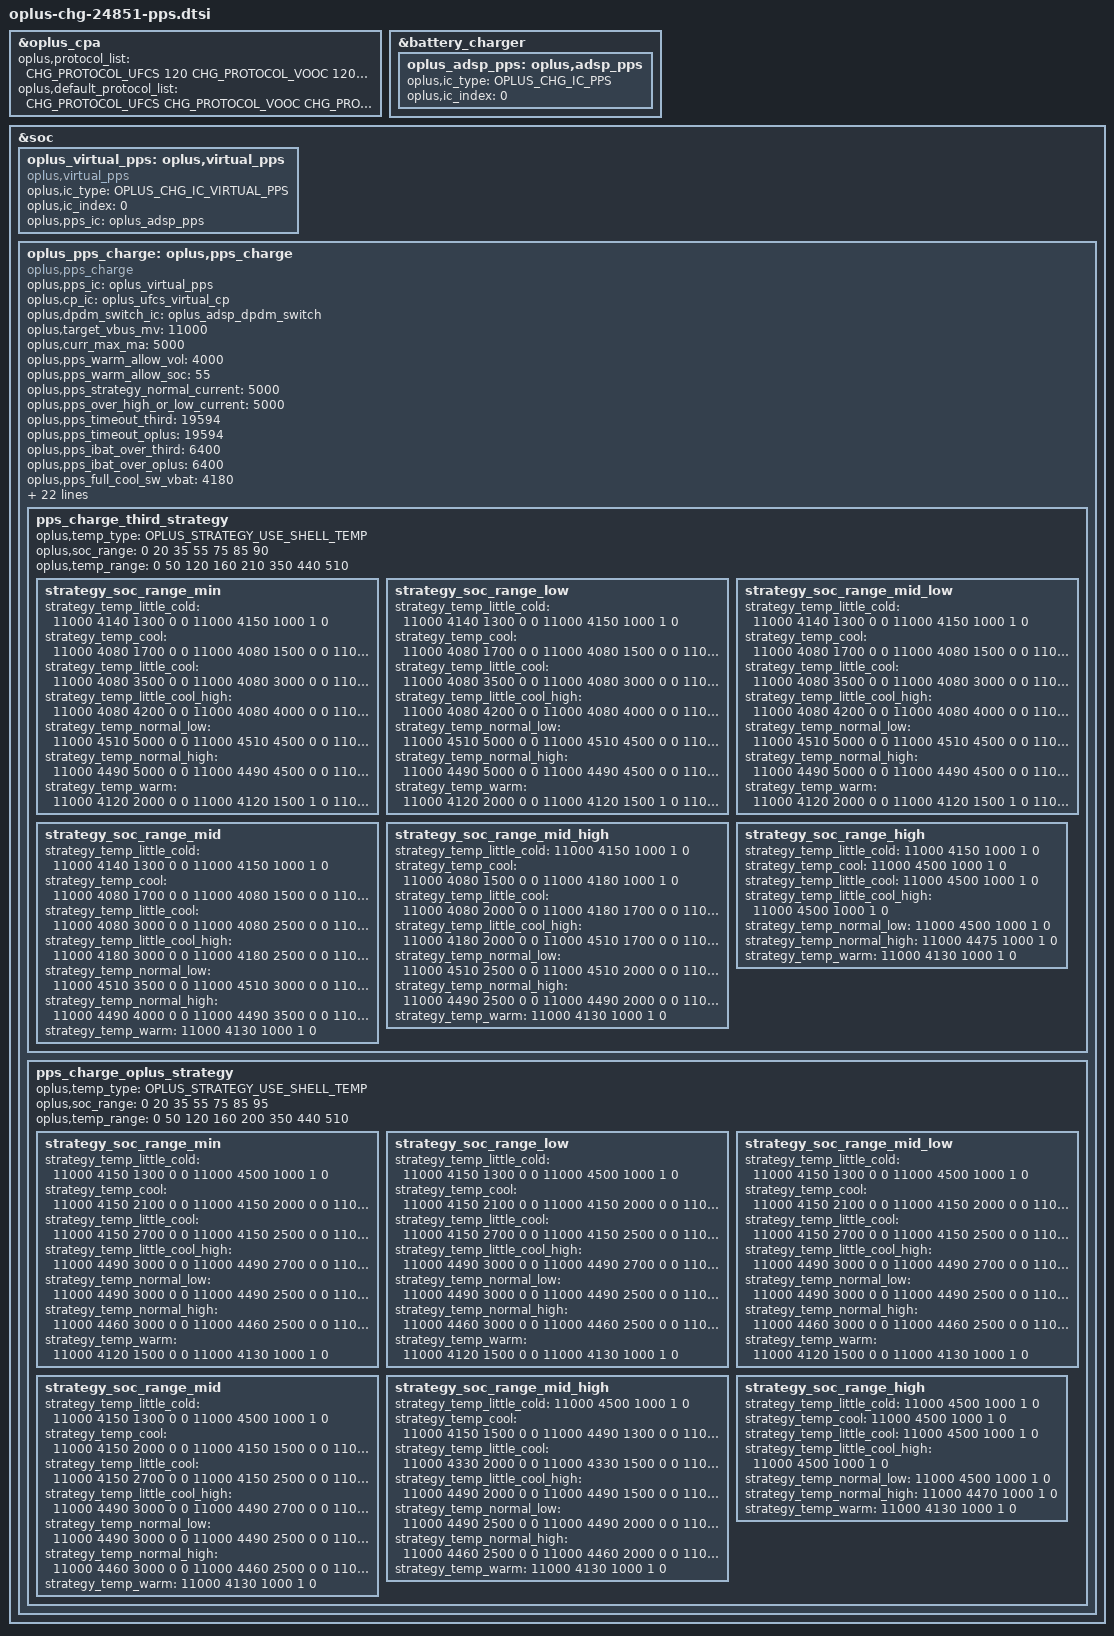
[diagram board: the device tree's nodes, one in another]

&oplus_cpa {
	oplus,protocol_list = <CHG_PROTOCOL_UFCS  120
				   CHG_PROTOCOL_VOOC 120
				   CHG_PROTOCOL_PPS  55
				   CHG_PROTOCOL_PD   18
				   CHG_PROTOCOL_QC   18>;
	oplus,default_protocol_list = <CHG_PROTOCOL_UFCS
					   CHG_PROTOCOL_VOOC
					   CHG_PROTOCOL_PPS
					   CHG_PROTOCOL_PD>;
};

&battery_charger {
	oplus_adsp_pps: oplus,adsp_pps {
		oplus,ic_type = <OPLUS_CHG_IC_PPS>;
		oplus,ic_index = <0>;
	};
};

&soc {
	oplus_virtual_pps: oplus,virtual_pps {
		compatible = "oplus,virtual_pps";

		oplus,ic_type = <OPLUS_CHG_IC_VIRTUAL_PPS>;
		oplus,ic_index = <0>;
		oplus,pps_ic = <&oplus_adsp_pps>;
	};
	oplus_pps_charge: oplus,pps_charge {
		compatible = "oplus,pps_charge";
		oplus,pps_ic = <&oplus_virtual_pps>;
		oplus,cp_ic = <&oplus_ufcs_virtual_cp>;
		oplus,dpdm_switch_ic = <&oplus_adsp_dpdm_switch>;

		oplus,target_vbus_mv = <11000>;
		oplus,curr_max_ma = <5000>;

		oplus,pps_warm_allow_vol = <4000>;
		oplus,pps_warm_allow_soc = <55>;
		oplus,pps_strategy_normal_current = <5000>;
		oplus,pps_over_high_or_low_current = <5000>;
		oplus,pps_timeout_third = <19594>;
		oplus,pps_timeout_oplus = <19594>;
		oplus,pps_ibat_over_third = <6400>;
		oplus,pps_ibat_over_oplus = <6400>;
		oplus,pps_full_cool_sw_vbat = <4180>;
		oplus,pps_full_normal_sw_vbat = <4520>;
		oplus,pps_full_normal_hw_vbat = <4560>;
		oplus,pps_full_ffc_vbat = <4550>;
		oplus,pps_full_warm_vbat = <4130>;
		oplus,pps_full_cool_sw_vbat_third = <4180>;
		oplus,pps_full_normal_sw_vbat_third= <4520>;
		oplus,pps_full_normal_hw_vbat_third = <4560>;
		oplus,pps_current_change_timeout = <100>;
		oplus,pps_strategy_batt_high_temp = <410 420 430 400 410 420>;
		oplus,pps_strategy_high_current = <5000 5000 2000 5000 5000 5000>;
		oplus,pps_little_cool_high_temp = <210>;
		oplus,pps_low_temp = <50>;
		oplus,curve_strategy_name = "pps_ufcs_curve_v2";
		oplus,pps_charge_strategy_soc = <0 20 35 55 75 85>;
		oplus,pps_charge_strategy_temp = <50 50 120 160 350 440 510>;

		oplus,plc_strategy-data = <&cp_2t1_simple_strategy>;
		oplus,plc_strategy-names = "default";

		pps_charge_third_strategy {
			oplus,temp_type = <OPLUS_STRATEGY_USE_SHELL_TEMP>;
			oplus,soc_range = <0 20 35 55 75 85 90>;
			oplus,temp_range = <0 50 120 160 210 350 440 510>;

			strategy_soc_range_min {
				strategy_temp_little_cold =	<11000 4140 1300 0 0
								11000 4150 1000 1 0>;
				strategy_temp_cool =		<11000 4080 1700 0 0
								11000 4080 1500 0 0
								11000 4180 1000 1 0>;
				strategy_temp_little_cool =	<11000 4080 3500 0 0
								11000 4080 3000 0 0
								11000 4080 2500 0 0
								11000 4080 2000 0 0
								11000 4180 1700 0 0
								11000 4180 1500 0 0
								11000 4520 1000 1 0>;
				strategy_temp_little_cool_high = <11000 4080 4200 0 0
								11000 4080 4000 0 0
								11000 4180 3500 0 0
								11000 4180 3000 0 0
								11000 4180 2500 0 0
								11000 4180 2000 0 0
								11000 4510 1700 0 0
								11000 4510 1500 0 0
								11000 4520 1000 1 0>;
				strategy_temp_normal_low =	<11000 4510 5000 0 0
								11000 4510 4500 0 0
								11000 4510 4000 0 0
								11000 4510 3500 0 0
								11000 4510 3000 0 0
								11000 4510 2500 0 0
								11000 4510 2000 0 0
								11000 4510 1500 0 0
								11000 4520 1000 1 0>;
				strategy_temp_normal_high =	<11000 4490 5000 0 0
								11000 4490 4500 0 0
								11000 4490 4000 0 0
								11000 4490 3500 0 0
								11000 4490 3000 0 0
								11000 4490 2500 0 0
								11000 4490 2000 0 0
								11000 4490 1500 0 0
								11000 4500 1000 1 0>;
				strategy_temp_warm =		<11000 4120 2000 0 0
								11000 4120 1500 1 0
								11000 4130 1000 1 0>;
			};
			strategy_soc_range_low {
				strategy_temp_little_cold =	<11000 4140 1300 0 0
								11000 4150 1000 1 0>;
				strategy_temp_cool =		<11000 4080 1700 0 0
								11000 4080 1500 0 0
								11000 4180 1000 1 0>;
				strategy_temp_little_cool =	<11000 4080 3500 0 0
								11000 4080 3000 0 0
								11000 4080 2500 0 0
								11000 4080 2000 0 0
								11000 4180 1700 0 0
								11000 4180 1500 0 0
								11000 4520 1000 1 0>;
				strategy_temp_little_cool_high = <11000 4080 4200 0 0
								11000 4080 4000 0 0
								11000 4180 3500 0 0
								11000 4180 3000 0 0
								11000 4180 2500 0 0
								11000 4180 2000 0 0
								11000 4510 1700 0 0
								11000 4510 1500 0 0
								11000 4520 1000 1 0>;
				strategy_temp_normal_low =	<11000 4510 5000 0 0
								11000 4510 4500 0 0
								11000 4510 4000 0 0
								11000 4510 3500 0 0
								11000 4510 3000 0 0
								11000 4510 2500 0 0
								11000 4510 2000 0 0
								11000 4510 1500 0 0
								11000 4520 1000 1 0>;
				strategy_temp_normal_high =	<11000 4490 5000 0 0
								11000 4490 4500 0 0
								11000 4490 4000 0 0
								11000 4490 3500 0 0
								11000 4490 3000 0 0
								11000 4490 2500 0 0
								11000 4490 2000 0 0
								11000 4490 1500 0 0
								11000 4500 1000 1 0>;
				strategy_temp_warm =		<11000 4120 2000 0 0
								11000 4120 1500 1 0
								11000 4130 1000 1 0>;
			};
			strategy_soc_range_mid_low {
				strategy_temp_little_cold =	<11000 4140 1300 0 0
								11000 4150 1000 1 0>;
				strategy_temp_cool =		<11000 4080 1700 0 0
								11000 4080 1500 0 0
								11000 4180 1000 1 0>;
				strategy_temp_little_cool =	<11000 4080 3500 0 0
								11000 4080 3000 0 0
								11000 4080 2500 0 0
								11000 4080 2000 0 0
								11000 4180 1700 0 0
								11000 4180 1500 0 0
								11000 4520 1000 1 0>;
				strategy_temp_little_cool_high = <11000 4080 4200 0 0
								11000 4080 4000 0 0
								11000 4180 3500 0 0
								11000 4180 3000 0 0
								11000 4180 2500 0 0
								11000 4180 2000 0 0
								11000 4510 1700 0 0
								11000 4510 1500 0 0
								11000 4520 1000 1 0>;
				strategy_temp_normal_low =	<11000 4510 5000 0 0
								11000 4510 4500 0 0
								11000 4510 4000 0 0
								11000 4510 3500 0 0
								11000 4510 3000 0 0
								11000 4510 2500 0 0
								11000 4510 2000 0 0
								11000 4510 1500 0 0
								11000 4520 1000 1 0>;
				strategy_temp_normal_high =	<11000 4490 5000 0 0
								11000 4490 4500 0 0
								11000 4490 4000 0 0
								11000 4490 3500 0 0
								11000 4490 3000 0 0
								11000 4490 2500 0 0
								11000 4490 2000 0 0
								11000 4490 1500 0 0
								11000 4500 1000 1 0>;
				strategy_temp_warm =		<11000 4120 2000 0 0
								11000 4120 1500 1 0
								11000 4130 1000 1 0>;
			};
			strategy_soc_range_mid {
				strategy_temp_little_cold =	<11000 4140 1300 0 0
								11000 4150 1000 1 0>;
				strategy_temp_cool =		<11000 4080 1700 0 0
								11000 4080 1500 0 0
								11000 4180 1000 1 0>;
				strategy_temp_little_cool =	<11000 4080 3000 0 0
								11000 4080 2500 0 0
								11000 4080 2000 0 0
								11000 4180 1700 0 0
								11000 4180 1500 0 0
								11000 4520 1000 1 0>;
				strategy_temp_little_cool_high = <11000 4180 3000 0 0
								11000 4180 2500 0 0
								11000 4180 2000 0 0
								11000 4510 1700 0 0
								11000 4510 1500 0 0
								11000 4520 1000 1 0>;
				strategy_temp_normal_low =	<11000 4510 3500 0 0
								11000 4510 3000 0 0
								11000 4510 2500 0 0
								11000 4510 2000 0 0
								11000 4510 1500 0 0
								11000 4520 1000 1 0>;
				strategy_temp_normal_high =	<11000 4490 4000 0 0
								11000 4490 3500 0 0
								11000 4490 3000 0 0
								11000 4490 2500 0 0
								11000 4490 2000 0 0
								11000 4490 1500 0 0
								11000 4500 1000 1 0>;
				strategy_temp_warm =		<11000 4130 1000 1 0>;
			};
			strategy_soc_range_mid_high {
				strategy_temp_little_cold =	<11000 4150 1000 1 0>;
				strategy_temp_cool =		<11000 4080 1500 0 0
								11000 4180 1000 1 0>;
				strategy_temp_little_cool =	<11000 4080 2000 0 0
								11000 4180 1700 0 0
								11000 4180 1500 0 0
								11000 4520 1000 1 0>;
				strategy_temp_little_cool_high = <11000 4180 2000 0 0
								11000 4510 1700 0 0
								11000 4510 1500 0 0
								11000 4520 1000 1 0>;
				strategy_temp_normal_low =	<11000 4510 2500 0 0
								11000 4510 2000 0 0
								11000 4510 1500 0 0
								11000 4520 1000 1 0>;
				strategy_temp_normal_high =	<11000 4490 2500 0 0
								11000 4490 2000 0 0
								11000 4490 1500 0 0
								11000 4500 1000 1 0>;
				strategy_temp_warm =		<11000 4130 1000 1 0>;
			};
			strategy_soc_range_high {
				strategy_temp_little_cold =	<11000 4150 1000 1 0>;
				strategy_temp_cool =		<11000 4500 1000 1 0>;
				strategy_temp_little_cool =	<11000 4500 1000 1 0>;
				strategy_temp_little_cool_high = <11000 4500 1000 1 0>;
				strategy_temp_normal_low =	<11000 4500 1000 1 0>;
				strategy_temp_normal_high =	<11000 4475 1000 1 0>;
				strategy_temp_warm =		<11000 4130 1000 1 0>;
			};
		};

		pps_charge_oplus_strategy {
			oplus,temp_type = <OPLUS_STRATEGY_USE_SHELL_TEMP>;
			oplus,soc_range = <0 20 35 55 75 85 95>;
			oplus,temp_range = <0 50 120 160 200 350 440 510>;

			strategy_soc_range_min {
				strategy_temp_little_cold =	<11000 4150 1300 0 0
								11000 4500 1000 1 0>;
				strategy_temp_cool =		<11000 4150 2100 0 0
								11000 4150 2000 0 0
								11000 4150 1500 0 0
								11000 4490 1300 0 0
								11000 4500 1000 1 0>;
				strategy_temp_little_cool =	<11000 4150 2700 0 0
								11000 4150 2500 0 0
								11000 4330 2100 0 0
								11000 4330 2000 0 0
								11000 4330 1500 0 0
								11000 4490 1300 0 0
								11000 4500 1000 1 0>;
				strategy_temp_little_cool_high = <11000 4490 3000 0 0
								11000 4490 2700 0 0
								11000 4490 2500 0 0
								11000 4490 2000 0 0
								11000 4490 1500 0 0
								11000 4500 1000 1 0>;
				strategy_temp_normal_low =	<11000 4490 3000 0 0
								11000 4490 2500 0 0
								11000 4490 2000 0 0
								11000 4490 1500 0 0
								11000 4500 1000 1 0>;
				strategy_temp_normal_high =	<11000 4460 3000 0 0
								11000 4460 2500 0 0
								11000 4460 2000 0 0
								11000 4460 1500 0 0
								11000 4470 1000 1 0>;
				strategy_temp_warm =		<11000 4120 1500 0 0
								11000 4130 1000 1 0>;
			};
			strategy_soc_range_low {
				strategy_temp_little_cold =	<11000 4150 1300 0 0
								11000 4500 1000 1 0>;
				strategy_temp_cool =		<11000 4150 2100 0 0
								11000 4150 2000 0 0
								11000 4150 1500 0 0
								11000 4490 1300 0 0
								11000 4500 1000 1 0>;
				strategy_temp_little_cool =	<11000 4150 2700 0 0
								11000 4150 2500 0 0
								11000 4330 2100 0 0
								11000 4330 2000 0 0
								11000 4330 1500 0 0
								11000 4490 1300 0 0
								11000 4500 1000 1 0>;
				strategy_temp_little_cool_high = <11000 4490 3000 0 0
								11000 4490 2700 0 0
								11000 4490 2500 0 0
								11000 4490 2000 0 0
								11000 4490 1500 0 0
								11000 4500 1000 1 0>;
				strategy_temp_normal_low =	<11000 4490 3000 0 0
								11000 4490 2500 0 0
								11000 4490 2000 0 0
								11000 4490 1500 0 0
								11000 4500 1000 1 0>;
				strategy_temp_normal_high =	<11000 4460 3000 0 0
								11000 4460 2500 0 0
								11000 4460 2000 0 0
								11000 4460 1500 0 0
								11000 4470 1000 1 0>;
				strategy_temp_warm =		<11000 4120 1500 0 0
								11000 4130 1000 1 0>;
			};
			strategy_soc_range_mid_low {
				strategy_temp_little_cold =	<11000 4150 1300 0 0
								11000 4500 1000 1 0>;
				strategy_temp_cool =		<11000 4150 2100 0 0
								11000 4150 2000 0 0
								11000 4150 1500 0 0
								11000 4490 1300 0 0
								11000 4500 1000 1 0>;
				strategy_temp_little_cool =	<11000 4150 2700 0 0
								11000 4150 2500 0 0
								11000 4330 2100 0 0
								11000 4330 2000 0 0
								11000 4330 1500 0 0
								11000 4490 1300 0 0
								11000 4500 1000 1 0>;
				strategy_temp_little_cool_high = <11000 4490 3000 0 0
								11000 4490 2700 0 0
								11000 4490 2500 0 0
								11000 4490 2000 0 0
								11000 4490 1500 0 0
								11000 4500 1000 1 0>;
				strategy_temp_normal_low =	<11000 4490 3000 0 0
								11000 4490 2500 0 0
								11000 4490 2000 0 0
								11000 4490 1500 0 0
								11000 4500 1000 1 0>;
				strategy_temp_normal_high =	<11000 4460 3000 0 0
								11000 4460 2500 0 0
								11000 4460 2000 0 0
								11000 4460 1500 0 0
								11000 4470 1000 1 0>;
				strategy_temp_warm =		<11000 4120 1500 0 0
								11000 4130 1000 1 0>;
			};
			strategy_soc_range_mid {
				strategy_temp_little_cold =	<11000 4150 1300 0 0
								11000 4500 1000 1 0>;
				strategy_temp_cool =		<11000 4150 2000 0 0
								11000 4150 1500 0 0
								11000 4490 1300 0 0
								11000 4500 1000 1 0>;
				strategy_temp_little_cool =	<11000 4150 2700 0 0
								11000 4150 2500 0 0
								11000 4330 2100 0 0
								11000 4330 2000 0 0
								11000 4330 1500 0 0
								11000 4490 1300 0 0
								11000 4500 1000 1 0>;
				strategy_temp_little_cool_high = <11000 4490 3000 0 0
								11000 4490 2700 0 0
								11000 4490 2500 0 0
								11000 4490 2000 0 0
								11000 4490 1500 0 0
								11000 4500 1000 1 0>;
				strategy_temp_normal_low =	<11000 4490 3000 0 0
								11000 4490 2500 0 0
								11000 4490 2000 0 0
								11000 4490 1500 0 0
								11000 4500 1000 1 0>;
				strategy_temp_normal_high =	<11000 4460 3000 0 0
								11000 4460 2500 0 0
								11000 4460 2000 0 0
								11000 4460 1500 0 0
								11000 4470 1000 1 0>;
				strategy_temp_warm =		<11000 4130 1000 1 0>;
			};
			strategy_soc_range_mid_high {
				strategy_temp_little_cold =	<11000 4500 1000 1 0>;
				strategy_temp_cool =		<11000 4150 1500 0 0
								11000 4490 1300 0 0
								11000 4500 1000 1 0>;
				strategy_temp_little_cool =	<11000 4330 2000 0 0
								11000 4330 1500 0 0
								11000 4490 1300 0 0
								11000 4500 1000 1 0>;
				strategy_temp_little_cool_high = <11000 4490 2000 0 0
								11000 4490 1500 0 0
								11000 4500 1000 1 0>;
				strategy_temp_normal_low =	<11000 4490 2500 0 0
								11000 4490 2000 0 0
								11000 4490 1500 0 0
								11000 4500 1000 1 0>;
				strategy_temp_normal_high =	<11000 4460 2500 0 0
								11000 4460 2000 0 0
								11000 4460 1500 0 0
								11000 4470 1000 1 0>;
				strategy_temp_warm =		<11000 4130 1000 1 0>;
			};
			strategy_soc_range_high {
				strategy_temp_little_cold =	<11000 4500 1000 1 0>;
				strategy_temp_cool =		<11000 4500 1000 1 0>;
				strategy_temp_little_cool =	<11000 4500 1000 1 0>;
				strategy_temp_little_cool_high = <11000 4500 1000 1 0>;
				strategy_temp_normal_low =	<11000 4500 1000 1 0>;
				strategy_temp_normal_high =	<11000 4470 1000 1 0>;
				strategy_temp_warm =		<11000 4130 1000 1 0>;
			};
		};
	};
};
